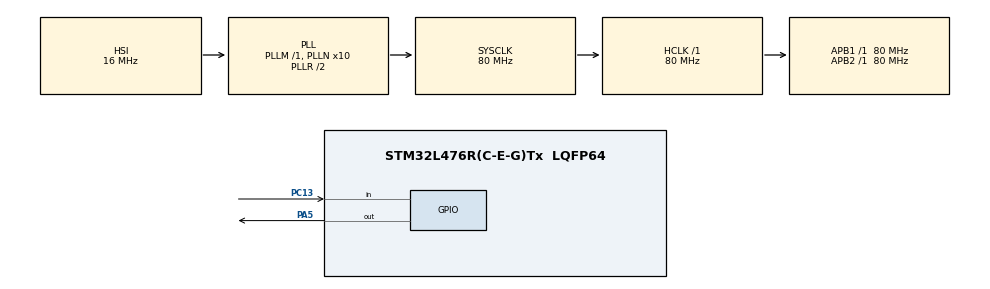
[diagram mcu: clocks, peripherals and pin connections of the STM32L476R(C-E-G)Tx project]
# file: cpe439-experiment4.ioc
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FREERTOS.Tasks01=defaultTask,24,128,StartDefaultTask,Default,NULL,Dynamic,NULL,NULL
FREERTOS.configUSE_NEWLIB_REENTRANT=1
Mcu.Family=STM32L4
Mcu.Name=STM32L476R(C-E-G)Tx
Mcu.Package=LQFP64
NVIC.PriorityGroup=NVIC_PRIORITYGROUP_4
NVIC.TIM6_DAC_IRQn=true\:15\:0\:false\:false\:true\:false\:false\:true\:true
NVIC.TimeBase=TIM6_DAC_IRQn
NVIC.TimeBaseIP=TIM6
PA5.Signal=GPIO_Output
PC13.Signal=GPIO_Input
ProjectManager.HeapSize=0x200
ProjectManager.StackSize=0x400
ProjectManager.TargetToolchain=STM32CubeIDE
RCC.ADCFreq_Value=64000000
RCC.AHBFreq_Value=80000000
RCC.APB1Freq_Value=80000000
RCC.APB1TimFreq_Value=80000000
RCC.APB2Freq_Value=80000000
RCC.APB2TimFreq_Value=80000000
RCC.CortexFreq_Value=80000000
RCC.HCLKFreq_Value=80000000
RCC.HSE_VALUE=8000000
RCC.HSI_VALUE=16000000
RCC.LSE_VALUE=32768
RCC.MSI_VALUE=4000000
RCC.PLLN=10
RCC.PLLSourceVirtual=RCC_PLLSOURCE_HSI
RCC.SYSCLKFreq_VALUE=80000000
RCC.SYSCLKSource=RCC_SYSCLKSOURCE_PLLCLK
RCC.USBFreq_Value=64000000
RCC.VCOOutputFreq_Value=160000000
VP_FREERTOS_VS_CMSIS_V2.Mode=CMSIS_V2
VP_SYS_VS_tim6.Mode=TIM6
board=custom

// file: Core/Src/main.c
/* USER CODE BEGIN Header */
/**
 ******************************************************************************
 * @file           : main.c
 * @brief          : Main program body
 ******************************************************************************
 * @attention
 *
 * Copyright (c) 2026 STMicroelectronics.
 * All rights reserved.
 *
 * This software is licensed under terms that can be found in the LICENSE file
 * in the root directory of this software component.
 * If no LICENSE file comes with this software, it is provided AS-IS.
 *
 ******************************************************************************
 */
/* USER CODE END Header */
#include "main.h"
#include "cmsis_os.h"
#include "event_groups.h"
#include <stdbool.h>

/* USER CODE BEGIN PD */
#define DELAY1_MS 				300
#define TASK1_BITS				(1 << 0)
#define TASK2_BITS				(1 << 1)
#define TASK3_BITS				(1 << 2)
#define STACK_SIZE				128 * 2
/* USER CODE END PD */

/* USER CODE BEGIN PM */
#define PA5_on() 				GPIOA->BSRR = (1 << 5);
#define PA5_off() 				GPIOA->BRR = (1 << 5);
#define LED_status_toggle() 	led_status = !led_status;
#define PC13_is_on() 			(GPIOC->IDR & GPIO_PIN_13) == 0
#define PA5_handle() \
	if ( led_status ) { \
		PA5_on(); \
	} else { \
		PA5_off(); \
	}
/* USER CODE END PM */

/* Definitions for defaultTask */
osThreadId_t defaultTaskHandle;
const osThreadAttr_t defaultTask_attributes = {
	.name = "defaultTask",
	.stack_size = STACK_SIZE,
	.priority = (osPriority_t) osPriorityNormal
};

osThreadId_t firstTaskHandle;
const osThreadAttr_t firstTask_attributes = {
	.name = "firstTask",
	.stack_size = STACK_SIZE,
	.priority = (osPriority_t) osPriorityNormal
};

osThreadId_t secondTaskHandle;
const osThreadAttr_t secondTask_attributes = {
	.name = "secondTask",
	.stack_size = STACK_SIZE,
	.priority = (osPriority_t) osPriorityNormal
};

osThreadId_t thirdTaskHandle;
const osThreadAttr_t thirdTask_attributes = {
	.name = "thirdTask",
	.stack_size = STACK_SIZE,
	.priority = (osPriority_t) osPriorityNormal
};

osThreadId_t fourthTaskHandle;
const osThreadAttr_t fourthTask_attributes = {
	.name = "fourthTask",
	.stack_size = STACK_SIZE,
	.priority = (osPriority_t) osPriorityNormal
};

/* USER CODE BEGIN PV */
EventGroupHandle_t group;
bool led_status = false;
/* USER CODE END PV */

/* STM32 functions */
void SystemClock_Config(void);
static void MX_GPIO_Init(void);

/* Functions */
void debug_blink (int amount);

/* Task functions */
void StartDefaultTask(void *argument);
void FirstTask (void *argument);
void SecondTask (void *argument);
void ThirdTask (void *argument);
void FourthTask (void *argument);

int main(void) {
	/* MCU Configuration--------------------------------------------------------*/

	/* Reset of all peripherals, Initializes the Flash interface and the Systick. */
	HAL_Init();

	/* Configure the system clock */
	SystemClock_Config();

	/* Initialize all configured peripherals */
	MX_GPIO_Init();

	/* Init scheduler */
	osKernelInitialize();

	/* Create the thread(s) */
	/* creation of defaultTask */
	defaultTaskHandle = osThreadNew(StartDefaultTask, NULL,
			&defaultTask_attributes);

	/* Start scheduler */
	osKernelStart();

	/* We should never get here as control is now taken by the scheduler */

	/* Infinite loop */
	/* USER CODE BEGIN WHILE */
	while (1);
	/* USER CODE END 3 */
}

void SystemClock_Config(void) {
	RCC_OscInitTypeDef RCC_OscInitStruct = { 0 };
	RCC_ClkInitTypeDef RCC_ClkInitStruct = { 0 };

	/** Configure the main internal regulator output voltage
	 */
	if (HAL_PWREx_ControlVoltageScaling(PWR_REGULATOR_VOLTAGE_SCALE1)
			!= HAL_OK) {
		Error_Handler();
	}

	/** Initializes the RCC Oscillators according to the specified parameters
	 * in the RCC_OscInitTypeDef structure.
	 */
	RCC_OscInitStruct.OscillatorType = RCC_OSCILLATORTYPE_HSI;
	RCC_OscInitStruct.HSIState = RCC_HSI_ON;
	RCC_OscInitStruct.HSICalibrationValue = RCC_HSICALIBRATION_DEFAULT;
	RCC_OscInitStruct.PLL.PLLState = RCC_PLL_ON;
	RCC_OscInitStruct.PLL.PLLSource = RCC_PLLSOURCE_HSI;
	RCC_OscInitStruct.PLL.PLLM = 1;
	RCC_OscInitStruct.PLL.PLLN = 10;
	RCC_OscInitStruct.PLL.PLLP = RCC_PLLP_DIV7;
	RCC_OscInitStruct.PLL.PLLQ = RCC_PLLQ_DIV2;
	RCC_OscInitStruct.PLL.PLLR = RCC_PLLR_DIV2;
	if (HAL_RCC_OscConfig(&RCC_OscInitStruct) != HAL_OK) {
		Error_Handler();
	}

	/** Initializes the CPU, AHB and APB buses clocks
	 */
	RCC_ClkInitStruct.ClockType = RCC_CLOCKTYPE_HCLK | RCC_CLOCKTYPE_SYSCLK
			| RCC_CLOCKTYPE_PCLK1 | RCC_CLOCKTYPE_PCLK2;
	RCC_ClkInitStruct.SYSCLKSource = RCC_SYSCLKSOURCE_PLLCLK;
	RCC_ClkInitStruct.AHBCLKDivider = RCC_SYSCLK_DIV1;
	RCC_ClkInitStruct.APB1CLKDivider = RCC_HCLK_DIV1;
	RCC_ClkInitStruct.APB2CLKDivider = RCC_HCLK_DIV1;

	if (HAL_RCC_ClockConfig(&RCC_ClkInitStruct, FLASH_LATENCY_4) != HAL_OK) {
		Error_Handler();
	}
}

static void MX_GPIO_Init(void) {
	GPIO_InitTypeDef GPIO_InitStruct = { 0 };

	/* GPIO Ports Clock Enable */
	__HAL_RCC_GPIOC_CLK_ENABLE();
	__HAL_RCC_GPIOA_CLK_ENABLE();

	/*Configure GPIO pin Output Level */
	HAL_GPIO_WritePin(GPIOA, GPIO_PIN_5, GPIO_PIN_RESET);

	/*Configure GPIO pin : PC13 */
	GPIO_InitStruct.Pin = GPIO_PIN_13;
	GPIO_InitStruct.Mode = GPIO_MODE_INPUT;
	GPIO_InitStruct.Pull = GPIO_NOPULL;
	HAL_GPIO_Init(GPIOC, &GPIO_InitStruct);

	/*Configure GPIO pin : PA5 */
	GPIO_InitStruct.Pin = GPIO_PIN_5;
	GPIO_InitStruct.Mode = GPIO_MODE_OUTPUT_PP;
	GPIO_InitStruct.Pull = GPIO_NOPULL;
	GPIO_InitStruct.Speed = GPIO_SPEED_FREQ_LOW;
	HAL_GPIO_Init(GPIOA, &GPIO_InitStruct);

}

/* USER CODE BEGIN 4 */
void debug_blink (int amount) {
	for ( int i = 0; i < amount * 2; i++ ) {
		LED_status_toggle();
		PA5_handle();
		vTaskDelay(amount * 10);
	}
}
/* USER CODE END 4 */

void StartDefaultTask (void *argument) {
	group = xEventGroupCreate();

	firstTaskHandle = osThreadNew(FirstTask, NULL, &firstTask_attributes);

	secondTaskHandle = osThreadNew(SecondTask, NULL, &secondTask_attributes);

	thirdTaskHandle = osThreadNew(ThirdTask, NULL, &thirdTask_attributes);

	fourthTaskHandle = osThreadNew(FourthTask, NULL, &fourthTask_attributes);

	while (1);
}

void FirstTask (void *argument) {
	vTaskDelay(DELAY1_MS);

	xEventGroupSetBits(group, TASK1_BITS);

	while (1);
}

void SecondTask (void *argument) {
	xEventGroupWaitBits(
		group,
		TASK1_BITS,
		pdFALSE,
		pdTRUE,
		portMAX_DELAY
	);

	xEventGroupSetBits(group, TASK2_BITS);

	while (1);
}

void ThirdTask (void *argument) {
	xEventGroupWaitBits(
		group,
		TASK1_BITS | TASK2_BITS,
		pdFALSE,
		pdTRUE,
		portMAX_DELAY
	);

	while ( ! PC13_is_on() );

	xEventGroupSetBits(group, TASK3_BITS);

	while (1);
}

void FourthTask (void *argument) {
	xEventGroupWaitBits(
		group,
		TASK1_BITS | TASK2_BITS | TASK3_BITS,
		pdFALSE,
		pdTRUE,
		portMAX_DELAY
	);

	while (1) {
		debug_blink(25);
	}

	while (1);
}

void HAL_TIM_PeriodElapsedCallback(TIM_HandleTypeDef *htim) {
	if (htim->Instance == TIM6) {
		HAL_IncTick();
	}
}

void Error_Handler(void) {
	__disable_irq();
	while (1) {
	}
}
